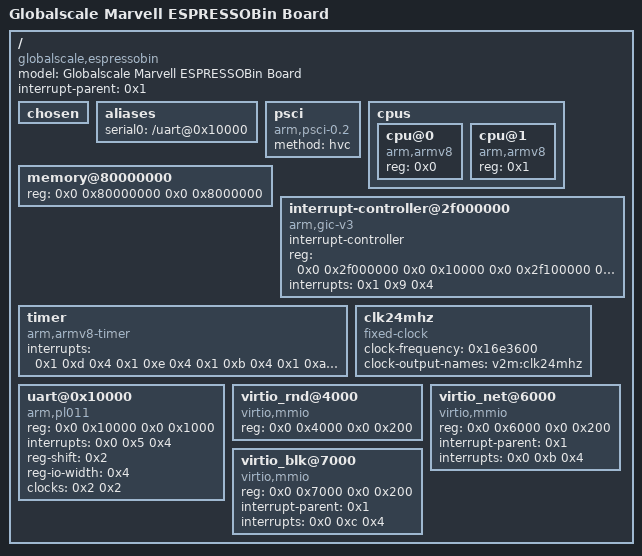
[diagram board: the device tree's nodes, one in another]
/dts-v1/;

/  {

	model = "Globalscale Marvell ESPRESSOBin Board";
	compatible = "globalscale,espressobin", "marvell,armada3720", "marvell,armada3710", "marvell,armada3700", "arm,vexpress";
	interrupt-parent = <0x1>;
	#address-cells = <0x2>;
	#size-cells = <0x2>;
	chosen {

	};
	aliases {

		serial0 = "/uart@0x10000";
	};
	psci {

		compatible = "arm,psci-0.2";
		method = "hvc";
	};
	cpus {

		#address-cells = <0x1>;
		#size-cells = <0x0>;
		cpu@0 {

			device_type = "cpu";
			compatible = "arm,armv8";
			reg = <0x0>;
		};
		cpu@1 {

			device_type = "cpu";
			compatible = "arm,armv8";
			reg = <0x1>;
		};
	};
	memory@80000000 {

		device_type = "memory";
		reg = <0x0 0x80000000 0x0 0x8000000>;
	};
	interrupt-controller@2f000000 {

		compatible = "arm,gic-v3";
		#interrupt-cells = <0x3>;
		#size-cells = <0x2>;
		interrupt-controller;
		reg = <0x0 0x2f000000 0x0 0x10000 0x0 0x2f100000 0x0 0x200000>;
		interrupts = <0x1 0x9 0x4>;
		phandle = <0x1>;
	};
	timer {

		compatible = "arm,armv8-timer";
		interrupts = <0x1 0xd 0x4 0x1 0xe 0x4 0x1 0xb 0x4 0x1 0xa 0x4>;
	};
	clk24mhz {

		compatible = "fixed-clock";
		#clock-cells = <0x0>;
		clock-frequency = <0x16e3600>;
		clock-output-names = "v2m:clk24mhz";
		phandle = <0x2>;
	};
	uart@0x10000 {

		compatible = "arm,pl011", "arm,primecell";
		reg = <0x0 0x10000 0x0 0x1000>;
		interrupts = <0x0 0x5 0x4>;
		reg-shift = <0x2>;
		reg-io-width = <0x4>;
		clocks = <0x2 0x2>;
		clock-names = "uartclk", "apb_pclk";
	};
	virtio_rnd@4000 {

		compatible = "virtio,mmio";
		reg = <0x0 0x4000 0x0 0x200>;
	};
	virtio_net@6000 {

		compatible = "virtio,mmio";
		reg = <0x0 0x6000 0x0 0x200>;
		interrupt-parent = <0x1>;
		interrupts = <0x0 0xb 0x4>;
	};
	virtio_blk@7000 {

		compatible = "virtio,mmio";
		reg = <0x0 0x7000 0x0 0x200>;
		interrupt-parent = <0x1>;
		interrupts = <0x0 0xc 0x4>;
	};
};
